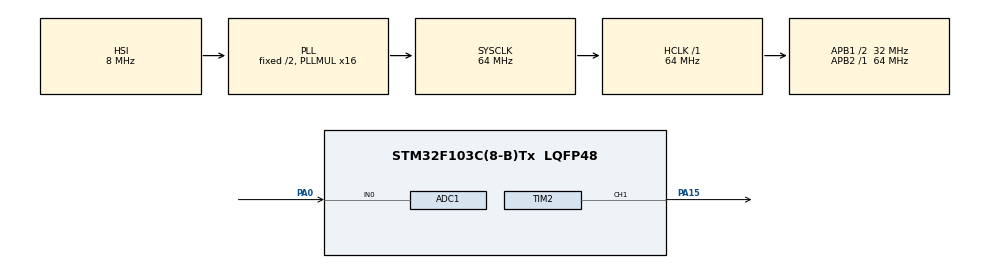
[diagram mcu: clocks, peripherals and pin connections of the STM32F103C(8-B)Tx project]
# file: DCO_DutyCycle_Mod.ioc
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ADC1.Channel-0\#ChannelRegularConversion=ADC_CHANNEL_0
ADC1.NbrOfConversionFlag=1
ADC1.Rank-0\#ChannelRegularConversion=1
ADC1.SamplingTime-0\#ChannelRegularConversion=ADC_SAMPLETIME_1CYCLE_5
ADC1.master=1
Mcu.Family=STM32F1
Mcu.Name=STM32F103C(8-B)Tx
Mcu.Package=LQFP48
NVIC.PriorityGroup=NVIC_PRIORITYGROUP_4
NVIC.TIM3_IRQn=true\:0\:0\:false\:false\:true\:true
PA0-WKUP.Signal=ADCx_IN0
PA13.Mode=Serial_Wire
PA13.Signal=SYS_JTMS-SWDIO
PA14.Mode=Serial_Wire
PA14.Signal=SYS_JTCK-SWCLK
PA15.Signal=S_TIM2_CH1_ETR
ProjectManager.HeapSize=0x200
ProjectManager.StackSize=0x400
ProjectManager.TargetToolchain=TrueSTUDIO
RCC.ADCPresc=RCC_ADCPCLK2_DIV6
RCC.AHBFreq_Value=64000000
RCC.APB1CLKDivider=RCC_HCLK_DIV2
RCC.APB1Freq_Value=32000000
RCC.APB1TimFreq_Value=64000000
RCC.APB2Freq_Value=64000000
RCC.APB2TimFreq_Value=64000000
RCC.HCLKFreq_Value=64000000
RCC.PLLMUL=RCC_PLL_MUL16
RCC.SYSCLKFreq_VALUE=64000000
RCC.SYSCLKSource=RCC_SYSCLKSOURCE_PLLCLK
RCC.USBFreq_Value=64000000
SH.ADCx_IN0.0=ADC1_IN0,IN0
SH.S_TIM2_CH1_ETR.0=TIM2_CH1,PWM Generation1 CH1
TIM2.Channel-PWM\ Generation1\ CH1=TIM_CHANNEL_1
TIM2.Period=199
TIM2.Prescaler=319
TIM2.Pulse-PWM\ Generation1\ CH1=99
TIM3.Period=49
TIM3.Prescaler=31999
VP_TIM2_VS_ClockSourceINT.Mode=Internal
VP_TIM3_VS_ClockSourceINT.Mode=Internal
board=custom

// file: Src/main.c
/* USER CODE BEGIN Header */
/**
  ******************************************************************************
  * @file           : main.c
  * @brief          : Main program body
  ******************************************************************************
  ** This notice applies to any and all portions of this file
  * that are not between comment pairs USER CODE BEGIN and
  * USER CODE END. Other portions of this file, whether
  * inserted by the user or by software development tools
  * are owned by their respective copyright owners.
  *
  * COPYRIGHT(c) 2019 STMicroelectronics
  *
  * Redistribution and use in source and binary forms, with or without modification,
  * are permitted provided that the following conditions are met:
  *   1. Redistributions of source code must retain the above copyright notice,
  *      this list of conditions and the following disclaimer.
  *   2. Redistributions in binary form must reproduce the above copyright notice,
  *      this list of conditions and the following disclaimer in the documentation
  *      and/or other materials provided with the distribution.
  *   3. Neither the name of STMicroelectronics nor the names of its contributors
  *      may be used to endorse or promote products derived from this software
  *      without specific prior written permission.
  *
  * THIS SOFTWARE IS PROVIDED BY THE COPYRIGHT HOLDERS AND CONTRIBUTORS "AS IS"
  * AND ANY EXPRESS OR IMPLIED WARRANTIES, INCLUDING, BUT NOT LIMITED TO, THE
  * IMPLIED WARRANTIES OF MERCHANTABILITY AND FITNESS FOR A PARTICULAR PURPOSE ARE
  * DISCLAIMED. IN NO EVENT SHALL THE COPYRIGHT HOLDER OR CONTRIBUTORS BE LIABLE
  * FOR ANY DIRECT, INDIRECT, INCIDENTAL, SPECIAL, EXEMPLARY, OR CONSEQUENTIAL
  * DAMAGES (INCLUDING, BUT NOT LIMITED TO, PROCUREMENT OF SUBSTITUTE GOODS OR
  * SERVICES; LOSS OF USE, DATA, OR PROFITS; OR BUSINESS INTERRUPTION) HOWEVER
  * CAUSED AND ON ANY THEORY OF LIABILITY, WHETHER IN CONTRACT, STRICT LIABILITY,
  * OR TORT (INCLUDING NEGLIGENCE OR OTHERWISE) ARISING IN ANY WAY OUT OF THE USE
  * OF THIS SOFTWARE, EVEN IF ADVISED OF THE POSSIBILITY OF SUCH DAMAGE.
  *
  ******************************************************************************
  */
/* USER CODE END Header */

#include "main.h"

ADC_HandleTypeDef hadc1;

TIM_HandleTypeDef htim2;
TIM_HandleTypeDef htim3;

/* USER CODE BEGIN PV */
float intensity_dc = 20;
float intensity_freq = 25;
/* USER CODE END PV */

void SystemClock_Config(void);
static void MX_GPIO_Init(void);
static void MX_ADC1_Init(void);
static void MX_TIM2_Init(void);
static void MX_TIM3_Init(void);
/* USER CODE BEGIN PFP */
uint16_t check_ADC(void);
/* USER CODE END PFP */

int main(void)
{

  /* MCU Configuration--------------------------------------------------------*/

  /* Reset of all peripherals, Initializes the Flash interface and the Systick. */
  HAL_Init();

  /* Configure the system clock */
  SystemClock_Config();

  /* Initialize all configured peripherals */
  MX_GPIO_Init();
  MX_ADC1_Init();
  MX_TIM2_Init();
  MX_TIM3_Init();
  /* USER CODE BEGIN 2 */
	HAL_TIM_Base_Start_IT(&htim3);

	HAL_TIM_PWM_Start(&htim2, TIM_CHANNEL_1);
	HAL_ADCEx_Calibration_Start(&hadc1);
  /* USER CODE END 2 */

  /* Infinite loop */
  while (1)
  {

  }
}

void SystemClock_Config(void)
{
  RCC_OscInitTypeDef RCC_OscInitStruct = {0};
  RCC_ClkInitTypeDef RCC_ClkInitStruct = {0};
  RCC_PeriphCLKInitTypeDef PeriphClkInit = {0};

  /**Initializes the CPU, AHB and APB busses clocks
  */
  RCC_OscInitStruct.OscillatorType = RCC_OSCILLATORTYPE_HSI;
  RCC_OscInitStruct.HSIState = RCC_HSI_ON;
  RCC_OscInitStruct.HSICalibrationValue = RCC_HSICALIBRATION_DEFAULT;
  RCC_OscInitStruct.PLL.PLLState = RCC_PLL_ON;
  RCC_OscInitStruct.PLL.PLLSource = RCC_PLLSOURCE_HSI_DIV2;
  RCC_OscInitStruct.PLL.PLLMUL = RCC_PLL_MUL16;
  if (HAL_RCC_OscConfig(&RCC_OscInitStruct) != HAL_OK)
  {
    Error_Handler();
  }
  /**Initializes the CPU, AHB and APB busses clocks
  */
  RCC_ClkInitStruct.ClockType = RCC_CLOCKTYPE_HCLK|RCC_CLOCKTYPE_SYSCLK
                              |RCC_CLOCKTYPE_PCLK1|RCC_CLOCKTYPE_PCLK2;
  RCC_ClkInitStruct.SYSCLKSource = RCC_SYSCLKSOURCE_PLLCLK;
  RCC_ClkInitStruct.AHBCLKDivider = RCC_SYSCLK_DIV1;
  RCC_ClkInitStruct.APB1CLKDivider = RCC_HCLK_DIV2;
  RCC_ClkInitStruct.APB2CLKDivider = RCC_HCLK_DIV1;

  if (HAL_RCC_ClockConfig(&RCC_ClkInitStruct, FLASH_LATENCY_2) != HAL_OK)
  {
    Error_Handler();
  }
  PeriphClkInit.PeriphClockSelection = RCC_PERIPHCLK_ADC;
  PeriphClkInit.AdcClockSelection = RCC_ADCPCLK2_DIV6;
  if (HAL_RCCEx_PeriphCLKConfig(&PeriphClkInit) != HAL_OK)
  {
    Error_Handler();
  }
}

static void MX_ADC1_Init(void)
{

  ADC_ChannelConfTypeDef sConfig = {0};

  /**Common config
  */
  hadc1.Instance = ADC1;
  hadc1.Init.ScanConvMode = ADC_SCAN_DISABLE;
  hadc1.Init.ContinuousConvMode = DISABLE;
  hadc1.Init.DiscontinuousConvMode = DISABLE;
  hadc1.Init.ExternalTrigConv = ADC_SOFTWARE_START;
  hadc1.Init.DataAlign = ADC_DATAALIGN_RIGHT;
  hadc1.Init.NbrOfConversion = 1;
  if (HAL_ADC_Init(&hadc1) != HAL_OK)
  {
    Error_Handler();
  }
  /**Configure Regular Channel
  */
  sConfig.Channel = ADC_CHANNEL_0;
  sConfig.Rank = ADC_REGULAR_RANK_1;
  sConfig.SamplingTime = ADC_SAMPLETIME_1CYCLE_5;
  if (HAL_ADC_ConfigChannel(&hadc1, &sConfig) != HAL_OK)
  {
    Error_Handler();
  }

}

static void MX_TIM2_Init(void)
{

  TIM_ClockConfigTypeDef sClockSourceConfig = {0};
  TIM_MasterConfigTypeDef sMasterConfig = {0};
  TIM_OC_InitTypeDef sConfigOC = {0};

  htim2.Instance = TIM2;
  htim2.Init.Prescaler = 319;
  htim2.Init.CounterMode = TIM_COUNTERMODE_UP;
  htim2.Init.Period = 199;
  htim2.Init.ClockDivision = TIM_CLOCKDIVISION_DIV1;
  htim2.Init.AutoReloadPreload = TIM_AUTORELOAD_PRELOAD_DISABLE;
  if (HAL_TIM_Base_Init(&htim2) != HAL_OK)
  {
    Error_Handler();
  }
  sClockSourceConfig.ClockSource = TIM_CLOCKSOURCE_INTERNAL;
  if (HAL_TIM_ConfigClockSource(&htim2, &sClockSourceConfig) != HAL_OK)
  {
    Error_Handler();
  }
  if (HAL_TIM_PWM_Init(&htim2) != HAL_OK)
  {
    Error_Handler();
  }
  sMasterConfig.MasterOutputTrigger = TIM_TRGO_RESET;
  sMasterConfig.MasterSlaveMode = TIM_MASTERSLAVEMODE_DISABLE;
  if (HAL_TIMEx_MasterConfigSynchronization(&htim2, &sMasterConfig) != HAL_OK)
  {
    Error_Handler();
  }
  sConfigOC.OCMode = TIM_OCMODE_PWM1;
  sConfigOC.Pulse = 99;
  sConfigOC.OCPolarity = TIM_OCPOLARITY_HIGH;
  sConfigOC.OCFastMode = TIM_OCFAST_DISABLE;
  if (HAL_TIM_PWM_ConfigChannel(&htim2, &sConfigOC, TIM_CHANNEL_1) != HAL_OK)
  {
    Error_Handler();
  }
  HAL_TIM_MspPostInit(&htim2);

}

static void MX_TIM3_Init(void)
{

  TIM_ClockConfigTypeDef sClockSourceConfig = {0};
  TIM_MasterConfigTypeDef sMasterConfig = {0};

  htim3.Instance = TIM3;
  htim3.Init.Prescaler = 31999;
  htim3.Init.CounterMode = TIM_COUNTERMODE_UP;
  htim3.Init.Period = 49;
  htim3.Init.ClockDivision = TIM_CLOCKDIVISION_DIV1;
  htim3.Init.AutoReloadPreload = TIM_AUTORELOAD_PRELOAD_DISABLE;
  if (HAL_TIM_Base_Init(&htim3) != HAL_OK)
  {
    Error_Handler();
  }
  sClockSourceConfig.ClockSource = TIM_CLOCKSOURCE_INTERNAL;
  if (HAL_TIM_ConfigClockSource(&htim3, &sClockSourceConfig) != HAL_OK)
  {
    Error_Handler();
  }
  sMasterConfig.MasterOutputTrigger = TIM_TRGO_RESET;
  sMasterConfig.MasterSlaveMode = TIM_MASTERSLAVEMODE_DISABLE;
  if (HAL_TIMEx_MasterConfigSynchronization(&htim3, &sMasterConfig) != HAL_OK)
  {
    Error_Handler();
  }

}

static void MX_GPIO_Init(void)
{

  /* GPIO Ports Clock Enable */
  __HAL_RCC_GPIOA_CLK_ENABLE();

}

/* USER CODE BEGIN 4 */
uint16_t check_ADC(void){
	HAL_ADC_Start(&hadc1);
	HAL_ADC_PollForConversion(&hadc1, 1000);
	uint16_t data_adc = HAL_ADC_GetValue(&hadc1);
	HAL_ADC_Stop(&hadc1);
	return data_adc;
}

void HAL_TIM_PeriodElapsedCallback(TIM_HandleTypeDef *htim){
	if(htim==&htim3){

		float data_adc = check_ADC();
		float periodo_mod = 200*(1 - (intensity_freq/500)*(data_adc-2048)/2048);
		float duty_cycle = periodo_mod*(0.5 + (intensity_dc/100)*(data_adc-2048)/4095);

		__HAL_TIM_SET_COMPARE(&htim2, TIM_CHANNEL_1, duty_cycle);
		__HAL_TIM_SET_AUTORELOAD(&htim2, periodo_mod);
	}
}
/* USER CODE END 4 */

void Error_Handler(void)
{
}

/************************ (C) COPYRIGHT STMicroelectronics *****END OF FILE****/
